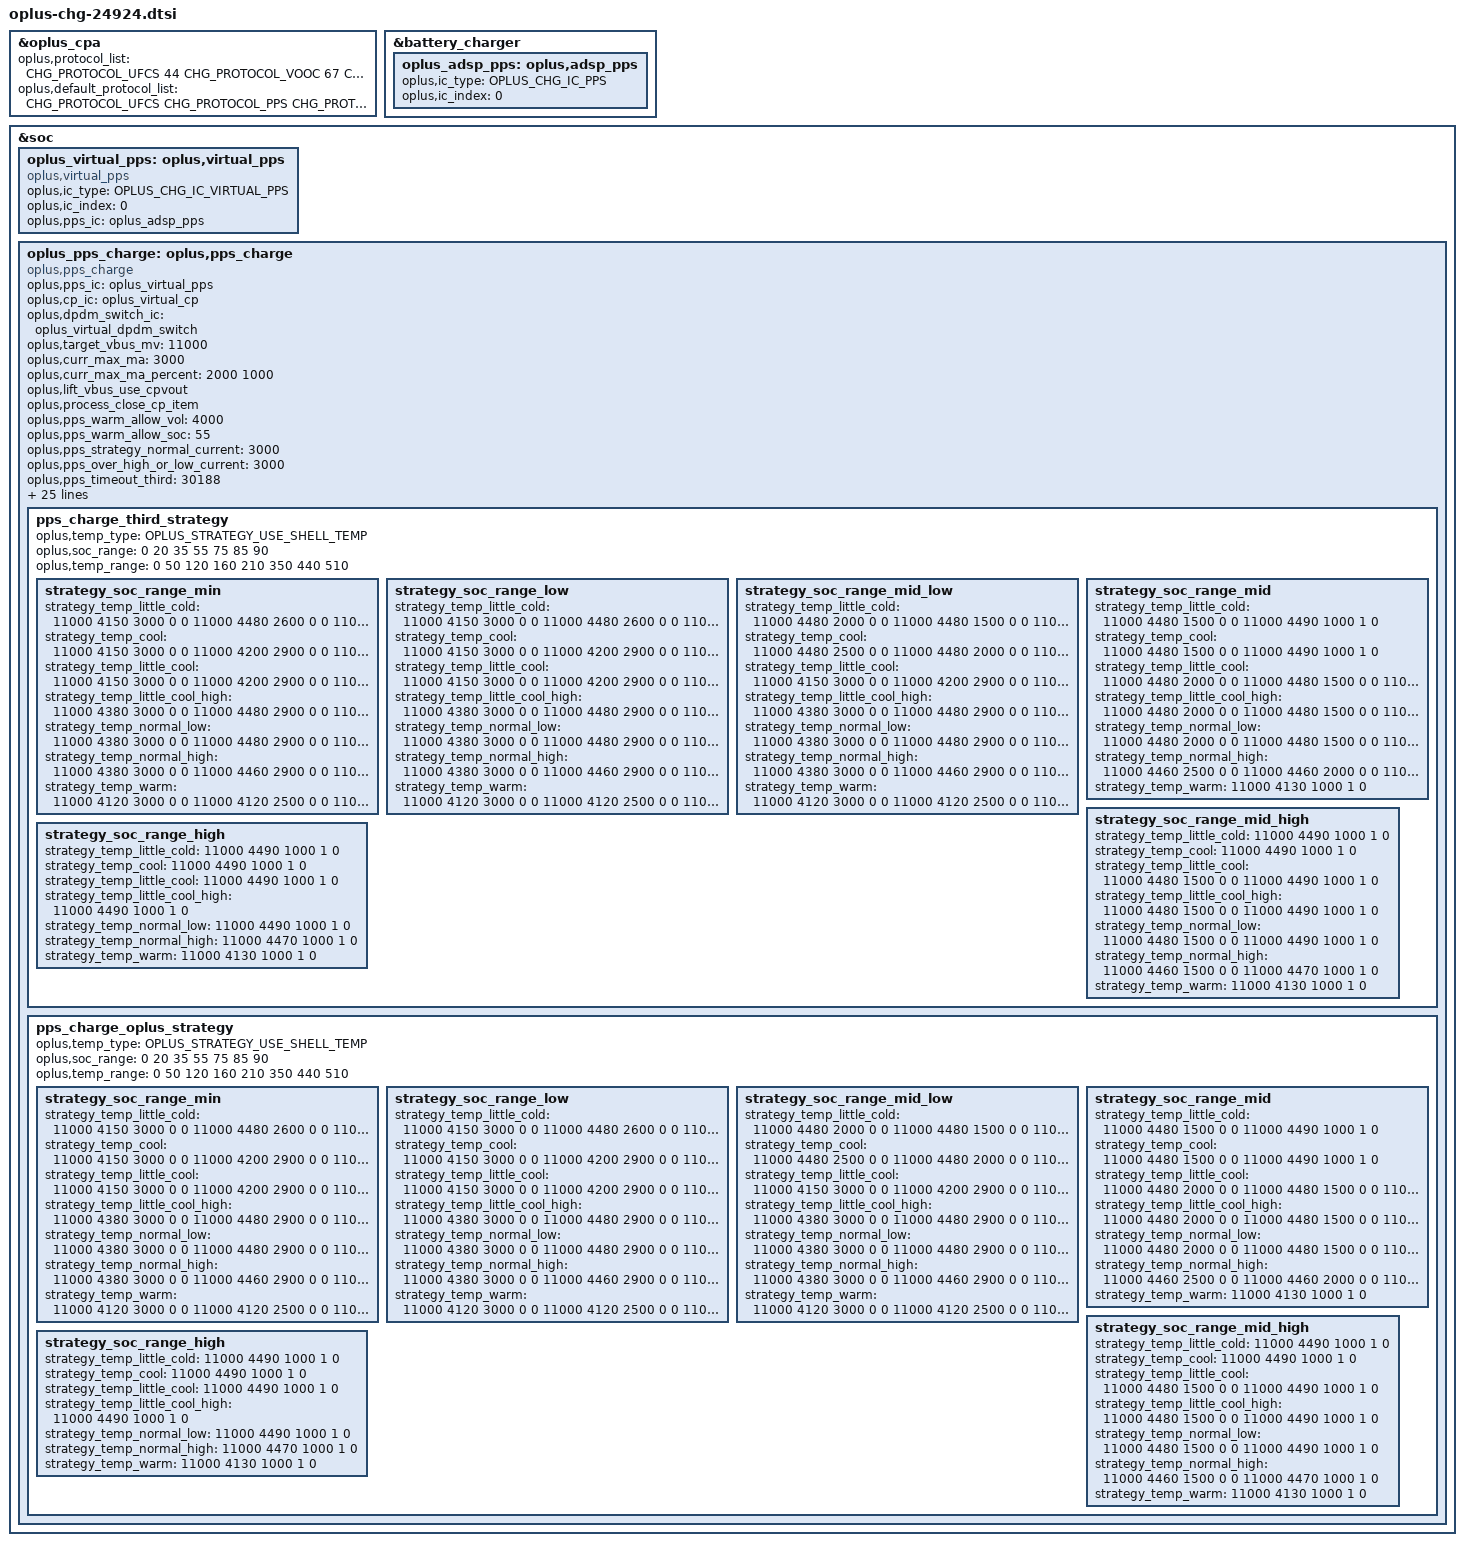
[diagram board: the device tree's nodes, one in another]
/* qcom battery gauge, svooc-67w, ufcs-44w, pps-33w */
#include "oplus-chg-erhai-common.dtsi"
#include "oplus-chg-qbg.dtsi"

&oplus_cpa {
	oplus,protocol_list = <CHG_PROTOCOL_UFCS 44
				CHG_PROTOCOL_VOOC 67
				CHG_PROTOCOL_PPS  33
				CHG_PROTOCOL_PD   18
				CHG_PROTOCOL_QC   18>;
	oplus,default_protocol_list = <CHG_PROTOCOL_UFCS
					CHG_PROTOCOL_PPS
					CHG_PROTOCOL_PD
					CHG_PROTOCOL_VOOC>;
};

/* PPS */
&battery_charger {
	oplus_adsp_pps: oplus,adsp_pps {
		oplus,ic_type = <OPLUS_CHG_IC_PPS>;
		oplus,ic_index = <0>;
	};
};

&soc {
	oplus_virtual_pps: oplus,virtual_pps {
		compatible = "oplus,virtual_pps";

		oplus,ic_type = <OPLUS_CHG_IC_VIRTUAL_PPS>;
		oplus,ic_index = <0>;
		oplus,pps_ic = <&oplus_adsp_pps>;
	};

	oplus_pps_charge: oplus,pps_charge {
		compatible = "oplus,pps_charge";
		oplus,pps_ic = <&oplus_virtual_pps>;
		oplus,cp_ic = <&oplus_virtual_cp>;
		oplus,dpdm_switch_ic = <&oplus_virtual_dpdm_switch>;

		oplus,target_vbus_mv = <11000>;
		oplus,curr_max_ma = <3000>;
		oplus,curr_max_ma_percent = <2000 /* 75% ibus */
					     1000 /* 85% ibus */>;
		oplus,lift_vbus_use_cpvout;
		oplus,process_close_cp_item;

		oplus,pps_warm_allow_vol = <4000>;
		oplus,pps_warm_allow_soc = <55>;
		oplus,pps_strategy_normal_current = <3000>;
		oplus,pps_over_high_or_low_current = <3000>;
		oplus,pps_timeout_third = <30188>;
		oplus,pps_timeout_oplus = <30188>;
		oplus,pps_ibat_over_third = <33 7400>;
		oplus,pps_ibat_over_oplus = <33 7400>;
		oplus,pps_full_cool_sw_vbat = <4490>;
		oplus,pps_full_normal_sw_vbat = <4490>;
		oplus,pps_full_normal_hw_vbat = <4540>;
		oplus,pps_full_ffc_vbat = <4485>;
		oplus,pps_full_warm_vbat = <4130>;
		oplus,pps_full_cool_sw_vbat_third = <4490>;
		oplus,pps_full_normal_sw_vbat_third= <4490>;
		oplus,pps_full_normal_hw_vbat_third = <4540>;
		oplus,pps_current_change_timeout = <100>;
		oplus,pps_strategy_batt_high_temp = <410 420 430 400 410 420>;
		oplus,pps_strategy_high_current = <3000 3000 2000 3000 3000 3000>;
		oplus,pps_little_cool_high_temp = <210>;
		oplus,curve_strategy_name = "pps_ufcs_curve_v2";
		oplus,pps_charge_strategy_soc = <0 20 35 55 75 85 85>;
		oplus,pps_charge_strategy_temp = <0 50 120 160 350 440 510>;
		oplus,temperature_strategy_name = "cgcl";
		oplus,temperature_strategy_data = <OPLUS_STRATEGY_USE_SHELL_TEMP
						0   385 7300 1 0
						375 405 5000 2 0
						395 420 4000 3 1
						410 430 3500 4 2
						420 440 2000 4 3>;
		pps_charge_third_strategy {
			oplus,temp_type = <OPLUS_STRATEGY_USE_SHELL_TEMP>;
			oplus,soc_range = <0 20 35 55 75 85 90>;
			oplus,temp_range = <0 50 120 160 210 350 440 510>;

			strategy_soc_range_min {
				strategy_temp_little_cold =	<11000 4150 3000 0 0
								11000 4480 2600 0 0
								11000 4480 2500 0 0
								11000 4480 2000 0 0
								11000 4480 1500 0 0
								11000 4490 1000 1 0>;
				strategy_temp_cool =		<11000 4150 3000 0 0
								11000 4200 2900 0 0
								11000 4480 2500 0 0
								11000 4480 2000 0 0
								11000 4480 1500 0 0
								11000 4490 1000 1 0>;
				strategy_temp_little_cool =	<11000 4150 3000 0 0
								11000 4200 2900 0 0
								11000 4480 2500 0 0
								11000 4480 2000 0 0
								11000 4480 1500 0 0
								11000 4490 1000 1 0>;
				strategy_temp_little_cool_high = <11000 4380 3000 0 0
								11000 4480 2900 0 0
								11000 4480 2500 0 0
								11000 4480 2000 0 0
								11000 4480 1500 0 0
								11000 4490 1000 1 0>;
				strategy_temp_normal_low =	<11000 4380 3000 0 0
								11000 4480 2900 0 0
								11000 4480 2500 0 0
								11000 4480 2000 0 0
								11000 4480 1500 0 0
								11000 4490 1000 1 0>;
				strategy_temp_normal_high =	<11000 4380 3000 0 0
								11000 4460 2900 0 0
								11000 4460 2500 0 0
								11000 4460 2000 0 0
								11000 4460 1500 0 0
								11000 4470 1000 1 0>;
				strategy_temp_warm =		<11000 4120 3000 0 0
								11000 4120 2500 0 0
								11000 4120 2000 0 0
								11000 4120 1500 0 0
								11000 4130 1000 1 0>;
			};
			strategy_soc_range_low {
				strategy_temp_little_cold =	<11000 4150 3000 0 0
								11000 4480 2600 0 0
								11000 4480 2500 0 0
								11000 4480 2000 0 0
								11000 4480 1500 0 0
								11000 4490 1000 1 0>;
				strategy_temp_cool =		<11000 4150 3000 0 0
								11000 4200 2900 0 0
								11000 4480 2500 0 0
								11000 4480 2000 0 0
								11000 4480 1500 0 0
								11000 4490 1000 1 0>;
				strategy_temp_little_cool =	<11000 4150 3000 0 0
								11000 4200 2900 0 0
								11000 4480 2500 0 0
								11000 4480 2000 0 0
								11000 4480 1500 0 0
								11000 4490 1000 1 0>;
				strategy_temp_little_cool_high = <11000 4380 3000 0 0
								11000 4480 2900 0 0
								11000 4480 2500 0 0
								11000 4480 2000 0 0
								11000 4480 1500 0 0
								11000 4490 1000 1 0>;
				strategy_temp_normal_low =	<11000 4380 3000 0 0
								11000 4480 2900 0 0
								11000 4480 2500 0 0
								11000 4480 2000 0 0
								11000 4480 1500 0 0
								11000 4490 1000 1 0>;
				strategy_temp_normal_high =	<11000 4380 3000 0 0
								11000 4460 2900 0 0
								11000 4460 2500 0 0
								11000 4460 2000 0 0
								11000 4460 1500 0 0
								11000 4470 1000 1 0>;
				strategy_temp_warm =		<11000 4120 3000 0 0
								11000 4120 2500 0 0
								11000 4120 2000 0 0
								11000 4120 1500 0 0
								11000 4130 1000 1 0>;
			};
			strategy_soc_range_mid_low {
				strategy_temp_little_cold =	<11000 4480 2000 0 0
								11000 4480 1500 0 0
								11000 4490 1000 1 0>;
				strategy_temp_cool =		<11000 4480 2500 0 0
								11000 4480 2000 0 0
								11000 4480 1500 0 0
								11000 4490 1000 1 0>;
				strategy_temp_little_cool =	<11000 4150 3000 0 0
								11000 4200 2900 0 0
								11000 4480 2500 0 0
								11000 4480 2000 0 0
								11000 4480 1500 0 0
								11000 4490 1000 1 0>;
				strategy_temp_little_cool_high = <11000 4380 3000 0 0
								11000 4480 2900 0 0
								11000 4480 2500 0 0
								11000 4480 2000 0 0
								11000 4480 1500 0 0
								11000 4490 1000 1 0>;
				strategy_temp_normal_low =	<11000 4380 3000 0 0
								11000 4480 2900 0 0
								11000 4480 2500 0 0
								11000 4480 2000 0 0
								11000 4480 1500 0 0
								11000 4490 1000 1 0>;
				strategy_temp_normal_high =	<11000 4380 3000 0 0
								11000 4460 2900 0 0
								11000 4460 2500 0 0
								11000 4460 2000 0 0
								11000 4460 1500 0 0
								11000 4470 1000 1 0>;
				strategy_temp_warm =		<11000 4120 3000 0 0
								11000 4120 2500 0 0
								11000 4120 2000 0 0
								11000 4120 1500 0 0
								11000 4130 1000 1 0>;
			};
			strategy_soc_range_mid {
				strategy_temp_little_cold =	<11000 4480 1500 0 0
								11000 4490 1000 1 0>;
				strategy_temp_cool =		<11000 4480 1500 0 0
								11000 4490 1000 1 0>;
				strategy_temp_little_cool =	<11000 4480 2000 0 0
								11000 4480 1500 0 0
								11000 4490 1000 1 0>;
				strategy_temp_little_cool_high = <11000 4480 2000 0 0
								11000 4480 1500 0 0
								11000 4490 1000 1 0>;
				strategy_temp_normal_low =	<11000 4480 2000 0 0
								11000 4480 1500 0 0
								11000 4490 1000 1 0>;
				strategy_temp_normal_high =	<11000 4460 2500 0 0
								11000 4460 2000 0 0
								11000 4460 1500 0 0
								11000 4470 1000 1 0>;
				strategy_temp_warm =		<11000 4130 1000 1 0>;
			};
			strategy_soc_range_mid_high {
				strategy_temp_little_cold =	<11000 4490 1000 1 0>;
				strategy_temp_cool =		<11000 4490 1000 1 0>;
				strategy_temp_little_cool =	<11000 4480 1500 0 0
								11000 4490 1000 1 0>;
				strategy_temp_little_cool_high = <11000 4480 1500 0 0
								11000 4490 1000 1 0>;
				strategy_temp_normal_low =	<11000 4480 1500 0 0
								11000 4490 1000 1 0>;
				strategy_temp_normal_high =	<11000 4460 1500 0 0
								11000 4470 1000 1 0>;
				strategy_temp_warm =		<11000 4130 1000 1 0>;
			};
			strategy_soc_range_high {
				strategy_temp_little_cold =	<11000 4490 1000 1 0>;
				strategy_temp_cool =		<11000 4490 1000 1 0>;
				strategy_temp_little_cool =	<11000 4490 1000 1 0>;
				strategy_temp_little_cool_high = <11000 4490 1000 1 0>;
				strategy_temp_normal_low =	<11000 4490 1000 1 0>;
				strategy_temp_normal_high =	<11000 4470 1000 1 0>;
				strategy_temp_warm =		<11000 4130 1000 1 0>;
			};
		};

		pps_charge_oplus_strategy {
			oplus,temp_type = <OPLUS_STRATEGY_USE_SHELL_TEMP>;
			oplus,soc_range = <0 20 35 55 75 85 90>;
			oplus,temp_range = <0 50 120 160 210 350 440 510>;

			strategy_soc_range_min {
				strategy_temp_little_cold =	<11000 4150 3000 0 0
								11000 4480 2600 0 0
								11000 4480 2500 0 0
								11000 4480 2000 0 0
								11000 4480 1500 0 0
								11000 4490 1000 1 0>;
				strategy_temp_cool =		<11000 4150 3000 0 0
								11000 4200 2900 0 0
								11000 4480 2500 0 0
								11000 4480 2000 0 0
								11000 4480 1500 0 0
								11000 4490 1000 1 0>;
				strategy_temp_little_cool =	<11000 4150 3000 0 0
								11000 4200 2900 0 0
								11000 4480 2500 0 0
								11000 4480 2000 0 0
								11000 4480 1500 0 0
								11000 4490 1000 1 0>;
				strategy_temp_little_cool_high = <11000 4380 3000 0 0
								11000 4480 2900 0 0
								11000 4480 2500 0 0
								11000 4480 2000 0 0
								11000 4480 1500 0 0
								11000 4490 1000 1 0>;
				strategy_temp_normal_low =	<11000 4380 3000 0 0
								11000 4480 2900 0 0
								11000 4480 2500 0 0
								11000 4480 2000 0 0
								11000 4480 1500 0 0
								11000 4490 1000 1 0>;
				strategy_temp_normal_high =	<11000 4380 3000 0 0
								11000 4460 2900 0 0
								11000 4460 2500 0 0
								11000 4460 2000 0 0
								11000 4460 1500 0 0
								11000 4470 1000 1 0>;
				strategy_temp_warm =		<11000 4120 3000 0 0
								11000 4120 2500 0 0
								11000 4120 2000 0 0
								11000 4120 1500 0 0
								11000 4130 1000 1 0>;
			};
			strategy_soc_range_low {
				strategy_temp_little_cold =	<11000 4150 3000 0 0
								11000 4480 2600 0 0
								11000 4480 2500 0 0
								11000 4480 2000 0 0
								11000 4480 1500 0 0
								11000 4490 1000 1 0>;
				strategy_temp_cool =		<11000 4150 3000 0 0
								11000 4200 2900 0 0
								11000 4480 2500 0 0
								11000 4480 2000 0 0
								11000 4480 1500 0 0
								11000 4490 1000 1 0>;
				strategy_temp_little_cool =	<11000 4150 3000 0 0
								11000 4200 2900 0 0
								11000 4480 2500 0 0
								11000 4480 2000 0 0
								11000 4480 1500 0 0
								11000 4490 1000 1 0>;
				strategy_temp_little_cool_high = <11000 4380 3000 0 0
								11000 4480 2900 0 0
								11000 4480 2500 0 0
								11000 4480 2000 0 0
								11000 4480 1500 0 0
								11000 4490 1000 1 0>;
				strategy_temp_normal_low =	<11000 4380 3000 0 0
								11000 4480 2900 0 0
								11000 4480 2500 0 0
								11000 4480 2000 0 0
								11000 4480 1500 0 0
								11000 4490 1000 1 0>;
				strategy_temp_normal_high =	<11000 4380 3000 0 0
								11000 4460 2900 0 0
								11000 4460 2500 0 0
								11000 4460 2000 0 0
								11000 4460 1500 0 0
								11000 4470 1000 1 0>;
				strategy_temp_warm =		<11000 4120 3000 0 0
								11000 4120 2500 0 0
								11000 4120 2000 0 0
								11000 4120 1500 0 0
								11000 4130 1000 1 0>;
			};
			strategy_soc_range_mid_low {
				strategy_temp_little_cold =	<11000 4480 2000 0 0
								11000 4480 1500 0 0
								11000 4490 1000 1 0>;
				strategy_temp_cool =		<11000 4480 2500 0 0
								11000 4480 2000 0 0
								11000 4480 1500 0 0
								11000 4490 1000 1 0>;
				strategy_temp_little_cool =	<11000 4150 3000 0 0
								11000 4200 2900 0 0
								11000 4480 2500 0 0
								11000 4480 2000 0 0
								11000 4480 1500 0 0
								11000 4490 1000 1 0>;
				strategy_temp_little_cool_high = <11000 4380 3000 0 0
								11000 4480 2900 0 0
								11000 4480 2500 0 0
								11000 4480 2000 0 0
								11000 4480 1500 0 0
								11000 4490 1000 1 0>;
				strategy_temp_normal_low =	<11000 4380 3000 0 0
								11000 4480 2900 0 0
								11000 4480 2500 0 0
								11000 4480 2000 0 0
								11000 4480 1500 0 0
								11000 4490 1000 1 0>;
				strategy_temp_normal_high =	<11000 4380 3000 0 0
								11000 4460 2900 0 0
								11000 4460 2500 0 0
								11000 4460 2000 0 0
								11000 4460 1500 0 0
								11000 4470 1000 1 0>;
				strategy_temp_warm =		<11000 4120 3000 0 0
								11000 4120 2500 0 0
								11000 4120 2000 0 0
								11000 4120 1500 0 0
								11000 4130 1000 1 0>;
			};
			strategy_soc_range_mid {
				strategy_temp_little_cold =	<11000 4480 1500 0 0
								11000 4490 1000 1 0>;
				strategy_temp_cool =		<11000 4480 1500 0 0
								11000 4490 1000 1 0>;
				strategy_temp_little_cool =	<11000 4480 2000 0 0
								11000 4480 1500 0 0
								11000 4490 1000 1 0>;
				strategy_temp_little_cool_high = <11000 4480 2000 0 0
								11000 4480 1500 0 0
								11000 4490 1000 1 0>;
				strategy_temp_normal_low =	<11000 4480 2000 0 0
								11000 4480 1500 0 0
								11000 4490 1000 1 0>;
				strategy_temp_normal_high =	<11000 4460 2500 0 0
								11000 4460 2000 0 0
								11000 4460 1500 0 0
								11000 4470 1000 1 0>;
				strategy_temp_warm =		<11000 4130 1000 1 0>;
			};
			strategy_soc_range_mid_high {
				strategy_temp_little_cold =	<11000 4490 1000 1 0>;
				strategy_temp_cool =		<11000 4490 1000 1 0>;
				strategy_temp_little_cool =	<11000 4480 1500 0 0
								11000 4490 1000 1 0>;
				strategy_temp_little_cool_high = <11000 4480 1500 0 0
								11000 4490 1000 1 0>;
				strategy_temp_normal_low =	<11000 4480 1500 0 0
								11000 4490 1000 1 0>;
				strategy_temp_normal_high =	<11000 4460 1500 0 0
								11000 4470 1000 1 0>;
				strategy_temp_warm =		<11000 4130 1000 1 0>;
			};
			strategy_soc_range_high {
				strategy_temp_little_cold =	<11000 4490 1000 1 0>;
				strategy_temp_cool =		<11000 4490 1000 1 0>;
				strategy_temp_little_cool =	<11000 4490 1000 1 0>;
				strategy_temp_little_cool_high = <11000 4490 1000 1 0>;
				strategy_temp_normal_low =	<11000 4490 1000 1 0>;
				strategy_temp_normal_high =	<11000 4470 1000 1 0>;
				strategy_temp_warm =		<11000 4130 1000 1 0>;
			};
		};
	};
};
